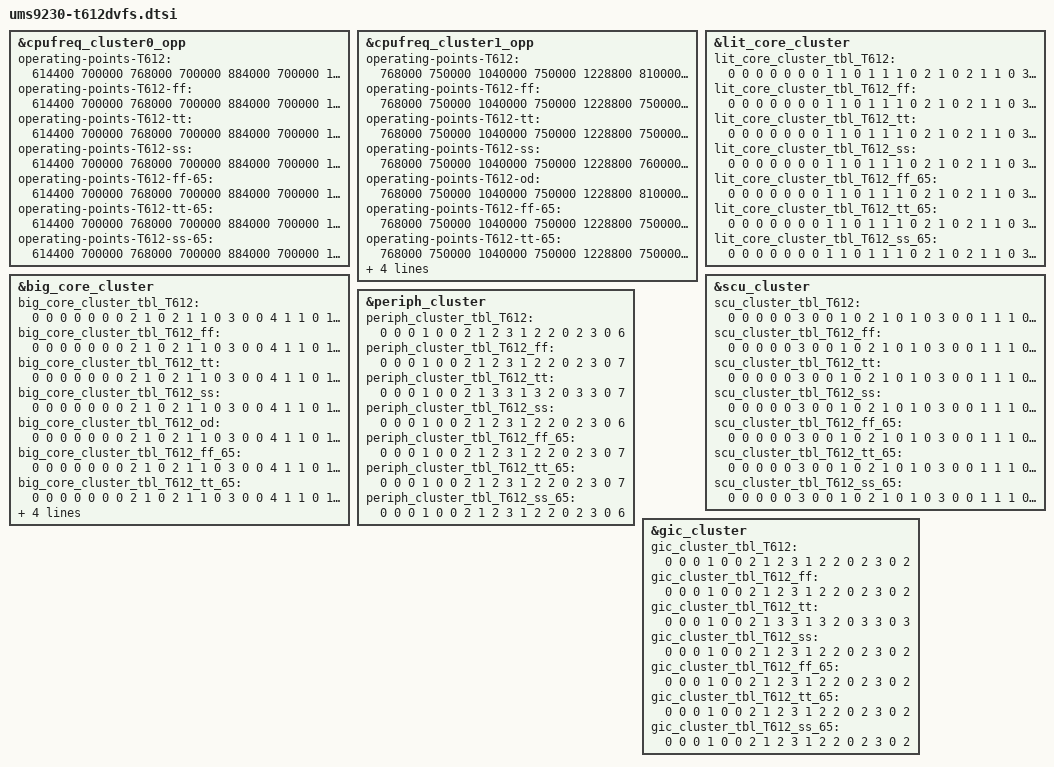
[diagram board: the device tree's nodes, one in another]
// SPDX-License-Identifier: (GPL-2.0+ OR MIT)
/*
 * Unisoc qogirl6 platform T612 SOC DVFS DTS file
 *
 * Copyright (C) 2021, Unisoc Communications Inc.
 */

#include "qogirl6.dtsi"
#include "ums9230.dtsi"

&cpufreq_cluster0_opp {
	/* operating-points-T612-0-0
	 * T606/T612-soc_ver 0-binning 0-temp
	 */
	operating-points-T612 = <
		/* kHZ   uV */
		614400  700000
		768000  700000
		884000  700000
		1040000 762500
		1228800 831250
		1378000 887500
		1536000 946875
		1612000 975000
		1716000 1012500
		1820000 1050000
	>;

	operating-points-T612-ff = <
		/* kHZ   uV */
		614400  700000
		768000  700000
		884000  700000
		1040000 700000
		1228800 762500
		1378000 815625
		1536000 868750
		1612000 896875
		1716000 931250
		1820000 965625
	>;

	operating-points-T612-tt = <
		/* kHZ   uV */
		614400  700000
		768000  700000
		884000  700000
		1040000 725000
		1228800 793750
		1378000 846875
		1536000 900000
		1612000 928125
		1716000 965625
		1820000 1000000
	>;

	operating-points-T612-ss = <
		/* kHZ   uV */
		614400  700000
		768000  700000
		884000  700000
		1040000 762500
		1228800 831250
		1378000 887500
		1536000 946875
		1612000 975000
		1716000 1012500
		1820000 1050000
	>;

	operating-points-T612-ff-65 = <
		/* kHZ   uV */
		614400  700000
		768000  700000
		884000  700000
		1040000 700000
		1228800 768750
		1378000 821875
		1536000 881250
		1612000 909375
		1716000 950000
		1820000 987500
	>;

	operating-points-T612-tt-65 = <
		/* kHZ   uV */
		614400  700000
		768000  700000
		884000  700000
		1040000 728125
		1228800 800000
		1378000 856250
		1536000 915625
		1612000 943750
		1716000 981250
		1820000 1021875
	>;

	operating-points-T612-ss-65 = <
		/* kHZ   uV */
		614400  700000
		768000  700000
		884000  700000
		1040000 765625
		1228800 837500
		1378000 896875
		1536000 959375
		1612000 990625
		1716000 1031250
	>;
};

&cpufreq_cluster1_opp {
	operating-points-T612 = <
		/* kHZ   uV */
		768000  750000
		1040000 750000
		1228800 810000
		1404000 870000
		1536000 910000
		1690000 960000
		1820000 1000000
	>;

	operating-points-T612-ff = <
		/* kHZ   uV */
		768000  750000
		1040000 750000
		1228800 750000
		1404000 750000
		1536000 780000
		1690000 830000
		1820000 870000
	>;

	operating-points-T612-tt = <
		/* kHZ   uV */
		768000  750000
		1040000 750000
		1228800 750000
		1404000 780000
		1536000 820000
		1690000 870000
		1820000 910000
	>;

	operating-points-T612-ss = <
		/* kHZ   uV */
		768000  750000
		1040000 750000
		1228800 760000
		1404000 820000
		1536000 860000
		1690000 910000
		1820000 950000
	>;

	operating-points-T612-od = <
		/* kHZ   uV */
		768000  750000
		1040000 750000
		1228800 810000
		1404000 870000
		1536000 910000
		1690000 960000
		1820000 1000000
	>;

	operating-points-T612-ff-65 = <
		/* kHZ   uV */
		768000  750000
		1040000 750000
		1228800 750000
		1404000 750000
		1536000 780000
		1690000 840000
		1820000 880000
	>;

	operating-points-T612-tt-65 = <
		/* kHZ   uV */
		768000  750000
		1040000 750000
		1228800 750000
		1404000 780000
		1536000 820000
		1690000 880000
		1820000 920000
	>;

	operating-points-T612-ss-65 = <
		/* kHZ   uV */
		768000  750000
		1040000 750000
		1228800 760000
		1404000 820000
		1536000 870000
		1690000 920000
		1820000 960000
	>;

	operating-points-T612-od-65 = <
		/* kHZ   uV */
		768000  750000
		1040000 750000
		1228800 820000
		1404000 870000
		1536000 920000
		1690000 970000
		1820000 1010000
	>;
};

&lit_core_cluster {
	/* lit_core_cluster_tbl_T612_0_0
	 * T606/T612-soc_ver 0-binning 0-temp
	 * sel, div, vol, vote_scu, vote_peri, vote_gic, mpllx
	 */
	lit_core_cluster_tbl_T612 = <
		0 0 0 0  0 0 0
		1 1 0 1  1 1 0
		2 1 0 2  1 1 0
		3 0 0 3  1 1 0
		3 0 1 4  1 1 1
		1 0 2 5  1 1 0
		3 0 3 6  4 4 2
		2 0 4 7  4 4 0
		3 0 5 8  4 5 3
		3 0 6 9  4 5 4
		3 0 7 10 4 5 5
	>;

	lit_core_cluster_tbl_T612_ff = <
		0 0 0 0  0 0 0
		1 1 0 1  1 1 0
		2 1 0 2  1 1 0
		3 0 0 3  1 1 0
		3 0 0 4  1 1 1
		1 0 1 5  1 1 0
		3 0 2 6  4 4 2
		2 0 3 7  4 4 0
		3 0 4 8  4 5 3
		3 0 5 9  4 5 4
		3 0 6 10 4 5 5
	>;

	lit_core_cluster_tbl_T612_tt = <
		0 0 0 0  0 0 0
		1 1 0 1  1 1 0
		2 1 0 2  1 1 0
		3 0 0 3  1 1 0
		3 0 1 4  1 1 1
		1 0 2 5  1 1 0
		3 0 3 6  4 4 2
		2 0 4 7  4 4 0
		3 0 5 8  4 5 3
		3 0 6 9  4 5 4
		3 0 7 10 4 5 5
	>;

	lit_core_cluster_tbl_T612_ss = <
		0 0 0 0  0 0 0
		1 1 0 1  1 1 0
		2 1 0 2  1 1 0
		3 0 0 3  1 1 0
		3 0 1 4  1 1 1
		1 0 2 5  1 1 0
		3 0 3 6  4 4 2
		2 0 4 7  4 4 0
		3 0 5 8  4 5 3
		3 0 6 9  4 5 4
		3 0 7 10 4 5 5
	>;

	lit_core_cluster_tbl_T612_ff_65 = <
		0 0 0 0  0 0 0
		1 1 0 1  1 1 0
		2 1 0 2  1 1 0
		3 0 0 3  1 1 0
		3 0 0 4  1 1 1
		1 0 1 5  1 1 0
		3 0 2 6  4 4 2
		2 0 3 7  4 4 0
		3 0 4 8  4 5 3
		3 0 5 9  4 5 4
		3 0 6 10 4 5 5
	>;

	lit_core_cluster_tbl_T612_tt_65 = <
		0 0 0 0  0 0 0
		1 1 0 1  1 1 0
		2 1 0 2  1 1 0
		3 0 0 3  1 1 0
		3 0 1 4  1 1 1
		1 0 2 5  1 1 0
		3 0 3 6  4 4 2
		2 0 4 7  4 4 0
		3 0 5 8  4 5 3
		3 0 6 9  4 5 4
		3 0 7 10 4 5 5
	>;

	lit_core_cluster_tbl_T612_ss_65 = <
		0 0 0 0  0 0 0
		1 1 0 1  1 1 0
		2 1 0 2  1 1 0
		3 0 0 3  1 1 0
		3 0 1 4  1 1 1
		1 0 2 5  1 1 0
		3 0 3 6  4 4 2
		2 0 4 7  4 4 0
		3 0 5 8  4 5 3
		3 0 6 9  4 5 4
		3 0 6 9  4 5 4
	>;
};

&big_core_cluster {
	/* sel, div, vol, vote_scu, vote_peri, vote_gic, mpllx */
	big_core_cluster_tbl_T612 = <
		0 0 0 0  0 0 0
		2 1 0 2  1 1 0
		3 0 0 4  1 1 0
		1 0 1 4  1 1 0
		3 0 2 6  4 4 1
		2 0 3 7  4 4 0
		3 0 4 8  4 5 3
		3 0 5 10 4 5 4
		3 0 5 10 4 5 4
		3 0 5 10 4 5 4
	>;

	big_core_cluster_tbl_T612_ff = <
		0 0 0 0  0 0 0
		2 1 0 2  1 1 0
		3 0 0 4  1 1 0
		1 0 0 4  1 1 0
		3 0 0 6  4 4 1
		2 0 1 7  4 4 0
		3 0 2 8  4 5 3
		3 0 3 10 4 5 4
		3 0 3 10 4 5 4
		3 0 3 10 4 5 4
	>;

	big_core_cluster_tbl_T612_tt = <
		0 0 0 0  0 0 0
		2 1 0 2  1 1 0
		3 0 0 4  1 1 0
		1 0 0 4  1 1 0
		3 0 1 6  4 4 1
		2 0 2 7  4 4 0
		3 0 3 8  4 5 3
		3 0 4 10 4 5 4
		3 0 4 10 4 5 4
		3 0 4 10 4 5 4
	>;

	big_core_cluster_tbl_T612_ss = <
		0 0 0 0  0 0 0
		2 1 0 2  1 1 0
		3 0 0 4  1 1 0
		1 0 1 4  1 1 0
		3 0 2 6  4 4 1
		2 0 3 7  4 4 0
		3 0 4 8  4 5 3
		3 0 5 10 4 5 4
		3 0 5 10 4 5 4
		3 0 5 10 4 5 4
	>;

	big_core_cluster_tbl_T612_od = <
		0 0 0 0  0 0 0
		2 1 0 2  1 1 0
		3 0 0 4  1 1 0
		1 0 1 4  1 1 0
		3 0 2 6  4 4 1
		2 0 3 7  4 4 0
		3 0 4 8  4 5 3
		3 0 5 10 4 5 4
		3 0 5 10 4 5 4
		3 0 5 10 4 5 4
	>;

	big_core_cluster_tbl_T612_ff_65 = <
		0 0 0 0  0 0 0
		2 1 0 2  1 1 0
		3 0 0 4  1 1 0
		1 0 0 4  1 1 0
		3 0 0 6  4 4 1
		2 0 1 7  4 4 0
		3 0 2 8  4 5 3
		3 0 3 10 4 5 4
		3 0 3 10 4 5 4
		3 0 3 10 4 5 4
	>;

	big_core_cluster_tbl_T612_tt_65 = <
		0 0 0 0  0 0 0
		2 1 0 2  1 1 0
		3 0 0 4  1 1 0
		1 0 0 4  1 1 0
		3 0 1 6  4 4 1
		2 0 2 7  4 4 0
		3 0 3 8  4 5 3
		3 0 4 10 4 5 4
		3 0 4 10 4 5 4
		3 0 4 10 4 5 4
	>;

	big_core_cluster_tbl_T612_ss_65 = <
		0 0 0 0  0 0 0
		2 1 0 2  1 1 0
		3 0 0 4  1 1 0
		1 0 1 4  1 1 0
		3 0 2 6  4 4 1
		2 0 3 7  4 4 0
		3 0 4 8  4 5 3
		3 0 5 10 4 5 4
		3 0 5 10 4 5 4
		3 0 5 10 4 5 4
	>;

	big_core_cluster_tbl_T612_od_65 = <
		0 0 0 0  0 0 0
		2 1 0 2  1 1 0
		3 0 0 4  1 1 0
		1 0 1 4  1 1 0
		3 0 2 6  4 4 1
		2 0 3 7  4 4 0
		3 0 4 8  4 5 3
		3 0 5 10 4 5 4
		3 0 5 10 4 5 4
		3 0 5 10 4 5 4
	>;
};

&scu_cluster {
	/* sel, div, vol, ace_div, mpllx */
	scu_cluster_tbl_T612 = <
		0 0 0 0 0
		3 0 0 1 0
		2 1 0 1 0
		3 0 0 1 1
		1 0 1 1 0
		3 0 2 1 2
		3 0 3 1 3
		2 0 4 1 0
		3 0 5 1 4
		3 0 6 1 5
		3 0 7 1 6
	>;

	scu_cluster_tbl_T612_ff = <
		0 0 0 0 0
		3 0 0 1 0
		2 1 0 1 0
		3 0 0 1 1
		1 0 0 1 0
		3 0 1 1 2
		3 0 2 1 3
		2 0 3 1 0
		3 0 4 1 4
		3 0 5 1 5
		3 0 6 1 6
	>;

	scu_cluster_tbl_T612_tt = <
		0 0 0 0 0
		3 0 0 1 0
		2 1 0 1 0
		3 0 0 1 1
		1 0 1 1 0
		3 0 2 1 2
		3 0 3 1 3
		2 0 4 1 0
		3 0 5 1 4
		3 0 6 1 5
		3 0 7 1 6
	>;

	scu_cluster_tbl_T612_ss = <
		0 0 0 0 0
		3 0 0 1 0
		2 1 0 1 0
		3 0 0 1 1
		1 0 1 1 0
		3 0 2 1 2
		3 0 3 1 3
		2 0 4 1 0
		3 0 5 1 4
		3 0 6 1 5
		3 0 7 1 6
	>;

	scu_cluster_tbl_T612_ff_65 = <
		0 0 0 0 0
		3 0 0 1 0
		2 1 0 1 0
		3 0 0 1 1
		1 0 0 1 0
		3 0 1 1 2
		3 0 2 1 3
		2 0 3 1 0
		3 0 4 1 4
		3 0 5 1 5
		3 0 6 1 6
	>;

	scu_cluster_tbl_T612_tt_65 = <
		0 0 0 0 0
		3 0 0 1 0
		2 1 0 1 0
		3 0 0 1 1
		1 0 1 1 0
		3 0 2 1 2
		3 0 3 1 3
		2 0 4 1 0
		3 0 5 1 4
		3 0 6 1 5
		3 0 7 1 6
	>;

	scu_cluster_tbl_T612_ss_65 = <
		0 0 0 0 0
		3 0 0 1 0
		2 1 0 1 0
		3 0 0 1 1
		1 0 1 1 0
		3 0 2 1 2
		3 0 3 1 3
		2 0 4 1 0
		3 0 5 1 4
		3 0 6 1 5
		3 0 6 1 5
	>;
};

&periph_cluster{
	/* sel, div, vol */
	periph_cluster_tbl_T612 = <
		0 0 0
		1 0 0
		2 1 2
		3 1 2
		2 0 2
		3 0 6
	>;

	periph_cluster_tbl_T612_ff = <
		0 0 0
		1 0 0
		2 1 2
		3 1 2
		2 0 2
		3 0 7
	>;

	periph_cluster_tbl_T612_tt = <
		0 0 0
		1 0 0
		2 1 3
		3 1 3
		2 0 3
		3 0 7
	>;

	periph_cluster_tbl_T612_ss = <
		0 0 0
		1 0 0
		2 1 2
		3 1 2
		2 0 2
		3 0 6
	>;

	periph_cluster_tbl_T612_ff_65 = <
		0 0 0
		1 0 0
		2 1 2
		3 1 2
		2 0 2
		3 0 7
	>;

	periph_cluster_tbl_T612_tt_65 = <
		0 0 0
		1 0 0
		2 1 2
		3 1 2
		2 0 2
		3 0 7
	>;

	periph_cluster_tbl_T612_ss_65 = <
		0 0 0
		1 0 0
		2 1 2
		3 1 2
		2 0 2
		3 0 6
	>;
};

&gic_cluster{
	/* sel, div, vol */
	gic_cluster_tbl_T612 = <
		0 0 0
		1 0 0
		2 1 2
		3 1 2
		2 0 2
		3 0 2
	>;

	gic_cluster_tbl_T612_ff = <
		0 0 0
		1 0 0
		2 1 2
		3 1 2
		2 0 2
		3 0 2
	>;

	gic_cluster_tbl_T612_tt = <
		0 0 0
		1 0 0
		2 1 3
		3 1 3
		2 0 3
		3 0 3
	>;

	gic_cluster_tbl_T612_ss = <
		0 0 0
		1 0 0
		2 1 2
		3 1 2
		2 0 2
		3 0 2
	>;

	gic_cluster_tbl_T612_ff_65 = <
		0 0 0
		1 0 0
		2 1 2
		3 1 2
		2 0 2
		3 0 2
	>;

	gic_cluster_tbl_T612_tt_65 = <
		0 0 0
		1 0 0
		2 1 2
		3 1 2
		2 0 2
		3 0 2
	>;

	gic_cluster_tbl_T612_ss_65 = <
		0 0 0
		1 0 0
		2 1 2
		3 1 2
		2 0 2
		3 0 2
	>;
};
